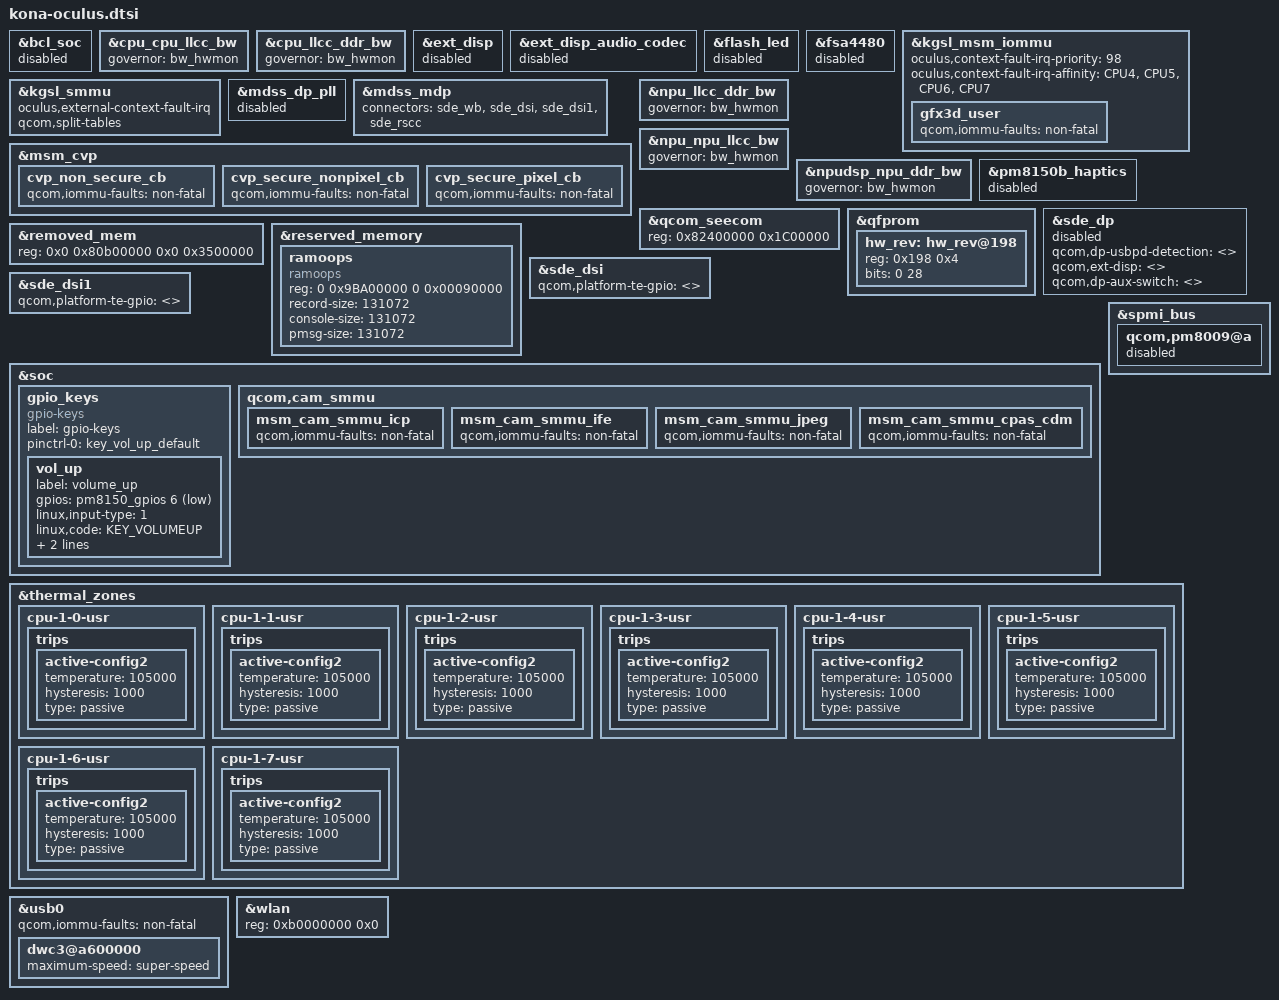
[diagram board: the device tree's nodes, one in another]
#include <dt-bindings/gpio/gpio.h>
#include <dt-bindings/input/input.h>

&bcl_soc {
	status = "disabled";
};

&cpu_cpu_llcc_bw {
	governor = "bw_hwmon";
};

&cpu_llcc_ddr_bw {
	governor = "bw_hwmon";
};

&ext_disp {
	status = "disabled";
};

&ext_disp_audio_codec {
	status = "disabled";
};

&flash_led {
	status = "disabled";
};

&fsa4480 {
	status = "disabled";
};

&kgsl_msm_iommu {
	oculus,context-fault-irq-priority = <98>;
	oculus,context-fault-irq-affinity = <&CPU4 &CPU5 &CPU6 &CPU7>;

	gfx3d_user {
		qcom,iommu-faults = "non-fatal";
	};
};

&kgsl_smmu {
	oculus,external-context-fault-irq;
	qcom,split-tables;
};

&mdss_dp_pll {
	status = "disabled";
};

&mdss_mdp {
	connectors = <&sde_wb &sde_dsi &sde_dsi1 &sde_rscc>;
};

&msm_cvp {
	cvp_non_secure_cb {
		qcom,iommu-faults = "non-fatal";
	};

	cvp_secure_nonpixel_cb {
		qcom,iommu-faults = "non-fatal";
	};

	cvp_secure_pixel_cb {
		qcom,iommu-faults = "non-fatal";
	};
};

&npu_llcc_ddr_bw {
	governor = "bw_hwmon";
};

&npu_npu_llcc_bw {
	governor = "bw_hwmon";
};

&npudsp_npu_ddr_bw {
	governor = "bw_hwmon";
};

&pm8150b_haptics {
	status = "disabled";
};

&qcom_seecom {
	reg = <0x82400000 0x1C00000>;
};

&qfprom {
	hw_rev: hw_rev@198 {
		reg = <0x198 0x4>;
		bits = <0 28>;
	};
};

&removed_mem {
	reg = <0x0 0x80b00000 0x0 0x3500000>;
};

&reserved_memory {
	ramoops: ramoops {
		compatible = "ramoops";
		reg = <0 0x9BA00000 0 0x00090000>;
		record-size = <131072>;
		console-size = <131072>;
		pmsg-size = <131072>;
	};
};

&sde_dp {
	status = "disabled";

	qcom,dp-usbpd-detection = <>;
	qcom,ext-disp = <>;
	qcom,dp-aux-switch = <>;
};

&sde_dsi {
	qcom,platform-te-gpio = <>;
};

&sde_dsi1 {
	qcom,platform-te-gpio = <>;
};

&soc {
	gpio_keys {
		compatible = "gpio-keys";
		label = "gpio-keys";

		pinctrl-names = "default";
		pinctrl-0 = <&key_vol_up_default>;

		vol_up {
			label = "volume_up";
			gpios = <&pm8150_gpios 6 GPIO_ACTIVE_LOW>;
			linux,input-type = <1>;
			linux,code = <KEY_VOLUMEUP>;
			debounce-interval = <15>;
			linux,can-disable;
		};
	};

	qcom,cam_smmu {
		msm_cam_smmu_icp {
			qcom,iommu-faults = "non-fatal";
		};

		msm_cam_smmu_ife {
			qcom,iommu-faults = "non-fatal";
		};

		msm_cam_smmu_jpeg {
			qcom,iommu-faults = "non-fatal";
		};

		msm_cam_smmu_cpas_cdm {
			qcom,iommu-faults = "non-fatal";
		};
	};
};

&spmi_bus {
	qcom,pm8009@a {
		status = "disabled";
	};
};

&thermal_zones {
	cpu-1-0-usr {
		trips {
			active-config2 {
				temperature = <105000>;
				hysteresis = <1000>;
				type = "passive";
			};
		};
	};

	cpu-1-1-usr {
		trips {
			active-config2 {
				temperature = <105000>;
				hysteresis = <1000>;
				type = "passive";
			};
		};
	};

	cpu-1-2-usr {
		trips {
			active-config2 {
				temperature = <105000>;
				hysteresis = <1000>;
				type = "passive";
			};
		};
	};

	cpu-1-3-usr {
		trips {
			active-config2 {
				temperature = <105000>;
				hysteresis = <1000>;
				type = "passive";
			};
		};
	};

	cpu-1-4-usr {
		trips {
			active-config2 {
				temperature = <105000>;
				hysteresis = <1000>;
				type = "passive";
			};
		};
	};

	cpu-1-5-usr {
		trips {
			active-config2 {
				temperature = <105000>;
				hysteresis = <1000>;
				type = "passive";
			};
		};
	};

	cpu-1-6-usr {
		trips {
			active-config2 {
				temperature = <105000>;
				hysteresis = <1000>;
				type = "passive";
			};
		};
	};

	cpu-1-7-usr {
		trips {
			active-config2 {
				temperature = <105000>;
				hysteresis = <1000>;
				type = "passive";
			};
		};
	};
};

&usb0 {
	qcom,iommu-faults = "non-fatal";

	dwc3@a600000 {
		maximum-speed = "super-speed";
	};
};

&wlan {
	reg = <0xb0000000 0x0>;
	reg-names = "";
};
